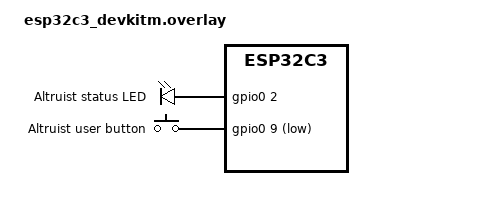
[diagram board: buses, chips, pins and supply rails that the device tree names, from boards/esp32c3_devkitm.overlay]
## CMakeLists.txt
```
cmake_minimum_required(VERSION 3.20.0)

find_package(Zephyr REQUIRED HINTS $ENV{ZEPHYR_BASE})
project(altruist_zephyr_firmware)

target_include_directories(app PUBLIC ${CMAKE_CURRENT_LIST_DIR}/include)

target_sources(app PRIVATE src/main.c)

if(CONFIG_ALTRUIST_CONFIG)
  target_sources(app PRIVATE
    src/config/config_defaults.c
    src/config/config_store.c
  )
endif()
if(EXISTS ${CMAKE_CURRENT_LIST_DIR}/src/crypto/CMakeLists.txt)
  add_subdirectory(src/crypto)
endif()
```

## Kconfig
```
menu "Altruist Zephyr Firmware"

config ALTRUIST_BOOT_MESSAGE
	string "Boot message"
	default "Altruist Zephyr bootstrap ready"
	help
	  Message printed during boot.

menu "WiFi and provisioning"

config ALTRUIST_WIFI_MANAGER
	bool "Enable Altruist WiFi manager"
	depends on NETWORKING && NET_MGMT && NET_MGMT_EVENT && WIFI
	default n
	help
	  Enables WiFi station lifecycle handling, reconnect policy and
	  provisioning entrypoints.

config ALTRUIST_WIFI_RECONNECT_INITIAL_BACKOFF_MS
	int "Initial reconnect backoff (ms)"
	depends on ALTRUIST_WIFI_MANAGER
	default 1000
	range 100 60000
	help
	  Delay used for the first reconnect retry after disconnect.
	  Valid range is 100 ms to 60000 ms (60 seconds).
	  If this exceeds max backoff, runtime clamps it to max backoff.

config ALTRUIST_WIFI_RECONNECT_MAX_BACKOFF_MS
	int "Maximum reconnect backoff (ms)"
	depends on ALTRUIST_WIFI_MANAGER
	default 30000
	range 1000 600000
	help
	  Upper bound used by exponential reconnect backoff.
	  Valid range is 1000 ms (1 second) to 600000 ms (10 minutes).
	  Long ceilings are intended for unstable or rate-limited networks.

config ALTRUIST_WIFI_MANAGER_TEST_SEAMS
	bool
	depends on ALTRUIST_WIFI_MANAGER
	default n
	help
	  Exposes deterministic time/event hooks used by unit tests.

config ALTRUIST_WIFI_CREDENTIALS_PERSISTENT_STORAGE
	bool "Enable persistent Wi-Fi credential storage"
	depends on ALTRUIST_WIFI_MANAGER
	select SETTINGS
	default y
	help
	  Stores Wi-Fi credentials in Zephyr Settings for persistence across reboots.
	  For secure storage at rest, ensure an encrypted/protected settings
	  backend is configured.

endmenu

source "Kconfig.variants"

endmenu
```

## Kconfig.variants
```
choice ALTRUIST_VARIANT
	prompt "Altruist product variant"
	default ALTRUIST_VARIANT_URBAN

config ALTRUIST_VARIANT_URBAN
	bool "Altruist Urban"

config ALTRUIST_VARIANT_INSIGHT
	bool "Altruist Insight"
endchoice

config ALTRUIST_FEATURE_DISPLAY
	bool "Enable display stack"
	default y if ALTRUIST_VARIANT_INSIGHT

config ALTRUIST_FEATURE_URBAN_AGGREGATION
	bool "Enable aggregation of Urban devices"
	default y if ALTRUIST_VARIANT_INSIGHT

config ALTRUIST_FEATURE_MDNS_DISCOVERY
	bool "Enable mDNS discovery"
	default y

config ALTRUIST_FEATURE_C3_REDUCED_PROFILE
	bool "Enable reduced C3 profile"
	default n
```

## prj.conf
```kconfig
CONFIG_LOG=y
CONFIG_LOG_DEFAULT_LEVEL=3
CONFIG_CONSOLE=y
CONFIG_PRINTK=y

# Settings
CONFIG_ALTRUIST_CONFIG=y
CONFIG_SETTINGS=y
CONFIG_SETTINGS_RUNTIME=y
CONFIG_SETTINGS_NVS=y
CONFIG_NVS=y
CONFIG_FLASH=y
CONFIG_FLASH_MAP=y
CONFIG_MPU_ALLOW_FLASH_WRITE=y

# Crypto identity
CONFIG_ALTRUIST_IDENTITY=y
CONFIG_ENTROPY_GENERATOR=y
CONFIG_PSA_WANT_KEY_TYPE_ECC_KEY_PAIR=y
CONFIG_SECURE_STORAGE=y
CONFIG_SECURE_STORAGE_ITS_STORE_IMPLEMENTATION_SETTINGS=y
CONFIG_MBEDTLS_ENABLE_HEAP=y
CONFIG_MBEDTLS_HEAP_SIZE=2048
# The default stack size is not enough for the PSA Crypto core.
# On top of that, the ITS implementation uses the stack for buffers.
CONFIG_MAIN_STACK_SIZE=4096
```

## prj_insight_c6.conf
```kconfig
CONFIG_ALTRUIST_VARIANT_INSIGHT=y
CONFIG_ALTRUIST_FEATURE_DISPLAY=y
CONFIG_ALTRUIST_FEATURE_URBAN_AGGREGATION=y
CONFIG_ALTRUIST_FEATURE_MDNS_DISCOVERY=y
CONFIG_ALTRUIST_FEATURE_C3_REDUCED_PROFILE=n
```

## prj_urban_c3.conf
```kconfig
CONFIG_ALTRUIST_VARIANT_URBAN=y
CONFIG_ALTRUIST_FEATURE_DISPLAY=n
CONFIG_ALTRUIST_FEATURE_URBAN_AGGREGATION=n
CONFIG_ALTRUIST_FEATURE_MDNS_DISCOVERY=n
CONFIG_ALTRUIST_FEATURE_C3_REDUCED_PROFILE=y
```

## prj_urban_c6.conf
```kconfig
CONFIG_ALTRUIST_VARIANT_URBAN=y
CONFIG_ALTRUIST_FEATURE_DISPLAY=n
CONFIG_ALTRUIST_FEATURE_URBAN_AGGREGATION=n
CONFIG_ALTRUIST_FEATURE_MDNS_DISCOVERY=y
CONFIG_ALTRUIST_FEATURE_C3_REDUCED_PROFILE=n
```

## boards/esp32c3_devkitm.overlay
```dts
#include <zephyr/dt-bindings/gpio/gpio.h>

/ {
	aliases {
		altruist-status-led = &altruist_status_led;
		altruist-user-button = &altruist_user_button;
		altruist-sensor-main = &altruist_sensor_main;
	};

	leds {
		compatible = "gpio-leds";

		altruist_status_led: altruist_status_led {
			gpios = <&gpio0 2 GPIO_ACTIVE_HIGH>;
			label = "Altruist status LED";
		};
	};

	buttons {
		compatible = "gpio-keys";

		altruist_user_button: altruist_user_button {
			gpios = <&gpio0 9 (GPIO_PULL_UP | GPIO_ACTIVE_LOW)>;
			label = "Altruist user button";
		};
	};

	altruist_sensor_main: altruist_sensor_main {
		compatible = "zephyr,user";
	};
};
```

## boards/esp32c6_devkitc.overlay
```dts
#include <zephyr/dt-bindings/gpio/gpio.h>

/ {
	aliases {
		altruist-status-led = &altruist_status_led;
		altruist-user-button = &altruist_user_button;
		altruist-sensor-main = &altruist_sensor_main;
	};

	leds {
		compatible = "gpio-leds";

		altruist_status_led: altruist_status_led {
			gpios = <&gpio0 8 GPIO_ACTIVE_HIGH>;
			label = "Altruist status LED";
		};
	};

	buttons {
		compatible = "gpio-keys";

		altruist_user_button: altruist_user_button {
			gpios = <&gpio0 9 (GPIO_PULL_UP | GPIO_ACTIVE_LOW)>;
			label = "Altruist user button";
		};
	};

	altruist_sensor_main: altruist_sensor_main {
		compatible = "zephyr,user";
	};
};
```

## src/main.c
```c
#include <zephyr/kernel.h>
#include <zephyr/sys/printk.h>
#include <zephyr/sys/util.h>

#include <altruist/identity.h>

#if defined(CONFIG_ALTRUIST_CONFIG)
#include <altruist/config.h>
#endif

int main(void)
{
	int rc = 0;

#if defined(CONFIG_ALTRUIST_CONFIG)
	rc = altruist_config_init();
#endif

	printk("%s\n", CONFIG_ALTRUIST_BOOT_MESSAGE);
#if defined(CONFIG_ALTRUIST_CONFIG)
	if (rc < 0) {
		printk("Config init failed: %d\n", rc);
	}
#endif
	printk("Running on board: %s\n", CONFIG_BOARD);

	if (IS_ENABLED(CONFIG_ALTRUIST_IDENTITY)) {
		rc = altruist_identity_init();
		if (rc != 0) {
			printk("Identity initialization failed (altruist_identity_init): %d\n", rc);
		}
	}

	return 0;
}
```
